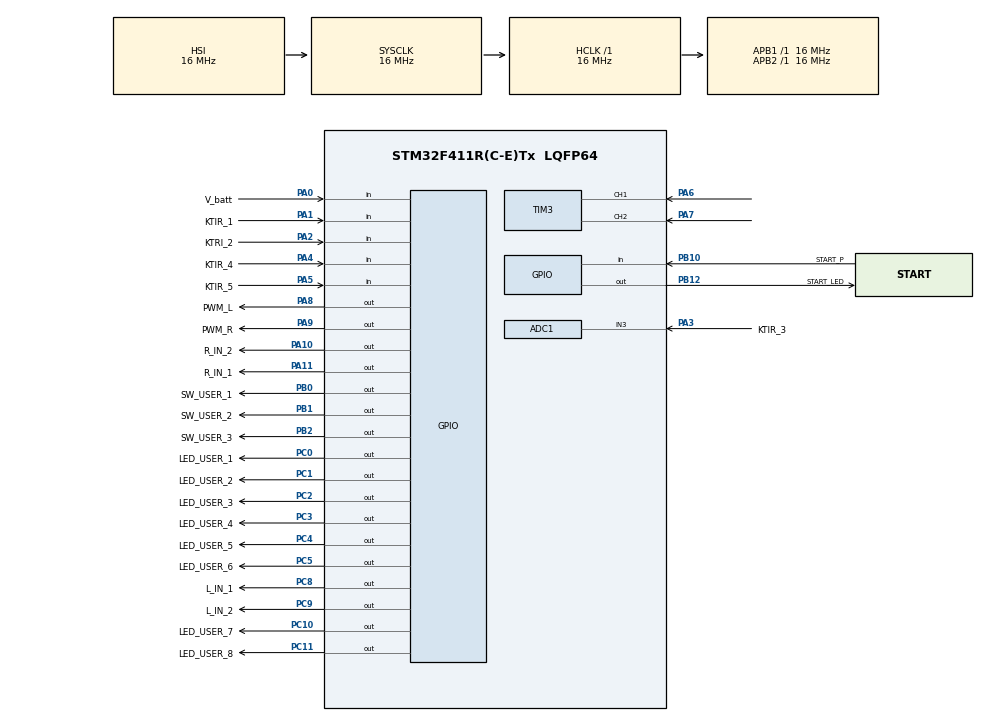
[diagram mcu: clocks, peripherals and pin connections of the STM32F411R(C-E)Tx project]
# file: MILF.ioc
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ADC1.Channel-0\#ChannelRegularConversion=ADC_CHANNEL_3
ADC1.NbrOfConversionFlag=1
ADC1.Rank-0\#ChannelRegularConversion=1
ADC1.SamplingTime-0\#ChannelRegularConversion=ADC_SAMPLETIME_3CYCLES
ADC1.master=1
Mcu.Family=STM32F4
Mcu.Name=STM32F411R(C-E)Tx
Mcu.Package=LQFP64
NVIC.PriorityGroup=NVIC_PRIORITYGROUP_4
PA0-WKUP.GPIO_Label=V_batt
PA0-WKUP.Signal=GPIO_Input
PA1.GPIO_Label=KTIR_1
PA1.Signal=GPIO_Input
PA10.GPIO_Label=R_IN_2
PA10.Signal=GPIO_Output
PA11.GPIO_Label=R_IN_1
PA11.Signal=GPIO_Output
PA13.GPIO_Label=SYS_SWDIO
PA13.Signal=SYS_JTMS-SWDIO
PA14.GPIO_Label=SYS_SWCLK
PA14.Signal=SYS_JTCK-SWCLK
PA2.GPIO_Label=KTRI_2
PA2.Signal=GPIO_Input
PA3.GPIO_Label=KTIR_3
PA3.Signal=ADCx_IN3
PA4.GPIO_Label=KTIR_4
PA4.Signal=GPIO_Input
PA5.GPIO_Label=KTIR_5
PA5.Signal=GPIO_Input
PA6.Signal=S_TIM3_CH1
PA7.Signal=S_TIM3_CH2
PA8.GPIO_Label=PWM_L
PA8.Signal=GPIO_Output
PA9.GPIO_Label=PWM_R
PA9.Signal=GPIO_Output
PB0.GPIO_Label=SW_USER_1
PB0.Signal=GPIO_Output
PB1.GPIO_Label=SW_USER_2
PB1.Signal=GPIO_Output
PB10.GPIO_Label=START_P
PB10.Signal=GPIO_Input
PB12.GPIO_Label=START_LED
PB12.Signal=GPIO_Output
PB2.GPIO_Label=SW_USER_3
PB2.Signal=GPIO_Output
PB6.Signal=USART1_TX
PB7.Signal=USART1_RX
PC0.GPIO_Label=LED_USER_1
PC0.Signal=GPIO_Output
PC1.GPIO_Label=LED_USER_2
PC1.Signal=GPIO_Output
PC10.GPIO_Label=LED_USER_7
PC10.Signal=GPIO_Output
PC11.GPIO_Label=LED_USER_8
PC11.Signal=GPIO_Output
PC2.GPIO_Label=LED_USER_3
PC2.Signal=GPIO_Output
PC3.GPIO_Label=LED_USER_4
PC3.Signal=GPIO_Output
PC4.GPIO_Label=LED_USER_5
PC4.Signal=GPIO_Output
PC5.GPIO_Label=LED_USER_6
PC5.Signal=GPIO_Output
PC6.Signal=USART6_TX
PC7.Signal=USART6_RX
PC8.GPIO_Label=L_IN_1
PC8.Signal=GPIO_Output
PC9.GPIO_Label=L_IN_2
PC9.Signal=GPIO_Output
ProjectManager.HeapSize=0x200
ProjectManager.StackSize=0x400
ProjectManager.TargetToolchain=STM32CubeIDE
RCC.AHBFreq_Value=16000000
RCC.APB1Freq_Value=16000000
RCC.APB2Freq_Value=16000000
RCC.CortexFreq_Value=16000000
RCC.HSE_VALUE=25000000
RCC.HSI_VALUE=16000000
RCC.LSE_VALUE=32768
RCC.SYSCLKFreq_VALUE=16000000
RCC.VCOOutputFreq_Value=192000000
SH.ADCx_IN3.0=ADC1_IN3,IN3
SH.S_TIM3_CH1.0=TIM3_CH1,Encoder_Interface
SH.S_TIM3_CH2.0=TIM3_CH2,Encoder_Interface
board=custom

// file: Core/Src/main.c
/* USER CODE BEGIN Header */
/**
  ******************************************************************************
  * @file           : main.c
  * @brief          : Main program body
  ******************************************************************************
  * @attention
  *
  * <h2><center>&copy; Copyright (c) 2021 STMicroelectronics.
  * All rights reserved.</center></h2>
  *
  * This software component is licensed by ST under BSD 3-Clause license,
  * the "License"; You may not use this file except in compliance with the
  * License. You may obtain a copy of the License at:
  *                        opensource.org/licenses/BSD-3-Clause
  *
  ******************************************************************************
  */
/* USER CODE END Header */
#include "main.h"

ADC_HandleTypeDef hadc1;

TIM_HandleTypeDef htim3;

void SystemClock_Config(void);
static void MX_GPIO_Init(void);
static void MX_ADC1_Init(void);
static void MX_TIM3_Init(void);

int main(void)
{

  /* MCU Configuration--------------------------------------------------------*/

  /* Reset of all peripherals, Initializes the Flash interface and the Systick. */
  HAL_Init();

  /* Configure the system clock */
  SystemClock_Config();

  /* Initialize all configured peripherals */
  MX_GPIO_Init();
  MX_ADC1_Init();
  MX_TIM3_Init();

  /* Infinite loop */
  /* USER CODE BEGIN WHILE */
  while (1)
  {
	  managedir();
    /* USER CODE END WHILE */

  }
}

void SystemClock_Config(void)
{
  RCC_OscInitTypeDef RCC_OscInitStruct = {0};
  RCC_ClkInitTypeDef RCC_ClkInitStruct = {0};

  /** Configure the main internal regulator output voltage
  */
  __HAL_RCC_PWR_CLK_ENABLE();
  __HAL_PWR_VOLTAGESCALING_CONFIG(PWR_REGULATOR_VOLTAGE_SCALE1);
  /** Initializes the RCC Oscillators according to the specified parameters
  * in the RCC_OscInitTypeDef structure.
  */
  RCC_OscInitStruct.OscillatorType = RCC_OSCILLATORTYPE_HSI;
  RCC_OscInitStruct.HSIState = RCC_HSI_ON;
  RCC_OscInitStruct.HSICalibrationValue = RCC_HSICALIBRATION_DEFAULT;
  RCC_OscInitStruct.PLL.PLLState = RCC_PLL_NONE;
  if (HAL_RCC_OscConfig(&RCC_OscInitStruct) != HAL_OK)
  {
    Error_Handler();
  }
  /** Initializes the CPU, AHB and APB buses clocks
  */
  RCC_ClkInitStruct.ClockType = RCC_CLOCKTYPE_HCLK|RCC_CLOCKTYPE_SYSCLK
                              |RCC_CLOCKTYPE_PCLK1|RCC_CLOCKTYPE_PCLK2;
  RCC_ClkInitStruct.SYSCLKSource = RCC_SYSCLKSOURCE_HSI;
  RCC_ClkInitStruct.AHBCLKDivider = RCC_SYSCLK_DIV1;
  RCC_ClkInitStruct.APB1CLKDivider = RCC_HCLK_DIV1;
  RCC_ClkInitStruct.APB2CLKDivider = RCC_HCLK_DIV1;

  if (HAL_RCC_ClockConfig(&RCC_ClkInitStruct, FLASH_LATENCY_0) != HAL_OK)
  {
    Error_Handler();
  }
}

static void MX_ADC1_Init(void)
{

  ADC_ChannelConfTypeDef sConfig = {0};

  /** Configure the global features of the ADC (Clock, Resolution, Data Alignment and number of conversion)
  */
  hadc1.Instance = ADC1;
  hadc1.Init.ClockPrescaler = ADC_CLOCK_SYNC_PCLK_DIV2;
  hadc1.Init.Resolution = ADC_RESOLUTION_12B;
  hadc1.Init.ScanConvMode = DISABLE;
  hadc1.Init.ContinuousConvMode = DISABLE;
  hadc1.Init.DiscontinuousConvMode = DISABLE;
  hadc1.Init.ExternalTrigConvEdge = ADC_EXTERNALTRIGCONVEDGE_NONE;
  hadc1.Init.ExternalTrigConv = ADC_SOFTWARE_START;
  hadc1.Init.DataAlign = ADC_DATAALIGN_RIGHT;
  hadc1.Init.NbrOfConversion = 1;
  hadc1.Init.DMAContinuousRequests = DISABLE;
  hadc1.Init.EOCSelection = ADC_EOC_SINGLE_CONV;
  if (HAL_ADC_Init(&hadc1) != HAL_OK)
  {
    Error_Handler();
  }
  /** Configure for the selected ADC regular channel its corresponding rank in the sequencer and its sample time.
  */
  sConfig.Channel = ADC_CHANNEL_3;
  sConfig.Rank = 1;
  sConfig.SamplingTime = ADC_SAMPLETIME_3CYCLES;
  if (HAL_ADC_ConfigChannel(&hadc1, &sConfig) != HAL_OK)
  {
    Error_Handler();
  }

}

static void MX_TIM3_Init(void)
{

  TIM_Encoder_InitTypeDef sConfig = {0};
  TIM_MasterConfigTypeDef sMasterConfig = {0};

  htim3.Instance = TIM3;
  htim3.Init.Prescaler = 0;
  htim3.Init.CounterMode = TIM_COUNTERMODE_UP;
  htim3.Init.Period = 65535;
  htim3.Init.ClockDivision = TIM_CLOCKDIVISION_DIV1;
  htim3.Init.AutoReloadPreload = TIM_AUTORELOAD_PRELOAD_DISABLE;
  sConfig.EncoderMode = TIM_ENCODERMODE_TI1;
  sConfig.IC1Polarity = TIM_ICPOLARITY_RISING;
  sConfig.IC1Selection = TIM_ICSELECTION_DIRECTTI;
  sConfig.IC1Prescaler = TIM_ICPSC_DIV1;
  sConfig.IC1Filter = 0;
  sConfig.IC2Polarity = TIM_ICPOLARITY_RISING;
  sConfig.IC2Selection = TIM_ICSELECTION_DIRECTTI;
  sConfig.IC2Prescaler = TIM_ICPSC_DIV1;
  sConfig.IC2Filter = 0;
  if (HAL_TIM_Encoder_Init(&htim3, &sConfig) != HAL_OK)
  {
    Error_Handler();
  }
  sMasterConfig.MasterOutputTrigger = TIM_TRGO_RESET;
  sMasterConfig.MasterSlaveMode = TIM_MASTERSLAVEMODE_DISABLE;
  if (HAL_TIMEx_MasterConfigSynchronization(&htim3, &sMasterConfig) != HAL_OK)
  {
    Error_Handler();
  }

}

static void MX_GPIO_Init(void)
{
  GPIO_InitTypeDef GPIO_InitStruct = {0};

  /* GPIO Ports Clock Enable */
  __HAL_RCC_GPIOC_CLK_ENABLE();
  __HAL_RCC_GPIOA_CLK_ENABLE();
  __HAL_RCC_GPIOB_CLK_ENABLE();

  /*Configure GPIO pin Output Level */
  HAL_GPIO_WritePin(GPIOC, LED_USER_1_Pin|LED_USER_2_Pin|LED_USER_3_Pin|LED_USER_4_Pin
                          |LED_USER_5_Pin|LED_USER_6_Pin|L_IN_1_Pin|L_IN_2_Pin
                          |LED_USER_7_Pin|LED_USER_8_Pin, GPIO_PIN_RESET);

  /*Configure GPIO pin Output Level */
  HAL_GPIO_WritePin(GPIOB, SW_USER_1_Pin|SW_USER_2_Pin|SW_USER_3_Pin|START_LED_Pin, GPIO_PIN_RESET);

  /*Configure GPIO pin Output Level */
  HAL_GPIO_WritePin(GPIOA, PWM_L_Pin|PWM_R_Pin|R_IN_2_Pin|R_IN_1_Pin, GPIO_PIN_RESET);

  /*Configure GPIO pins : LED_USER_1_Pin LED_USER_2_Pin LED_USER_3_Pin LED_USER_4_Pin
                           LED_USER_5_Pin LED_USER_6_Pin L_IN_1_Pin L_IN_2_Pin
                           LED_USER_7_Pin LED_USER_8_Pin */
  GPIO_InitStruct.Pin = LED_USER_1_Pin|LED_USER_2_Pin|LED_USER_3_Pin|LED_USER_4_Pin
                          |LED_USER_5_Pin|LED_USER_6_Pin|L_IN_1_Pin|L_IN_2_Pin
                          |LED_USER_7_Pin|LED_USER_8_Pin;
  GPIO_InitStruct.Mode = GPIO_MODE_OUTPUT_PP;
  GPIO_InitStruct.Pull = GPIO_NOPULL;
  GPIO_InitStruct.Speed = GPIO_SPEED_FREQ_LOW;
  HAL_GPIO_Init(GPIOC, &GPIO_InitStruct);

  /*Configure GPIO pins : V_batt_Pin KTIR_1_Pin KTRI_2_Pin KTIR_4_Pin
                           KTIR_5_Pin */
  GPIO_InitStruct.Pin = V_batt_Pin|KTIR_1_Pin|KTRI_2_Pin|KTIR_4_Pin
                          |KTIR_5_Pin;
  GPIO_InitStruct.Mode = GPIO_MODE_INPUT;
  GPIO_InitStruct.Pull = GPIO_NOPULL;
  HAL_GPIO_Init(GPIOA, &GPIO_InitStruct);

  /*Configure GPIO pins : SW_USER_1_Pin SW_USER_2_Pin SW_USER_3_Pin START_LED_Pin */
  GPIO_InitStruct.Pin = SW_USER_1_Pin|SW_USER_2_Pin|SW_USER_3_Pin|START_LED_Pin;
  GPIO_InitStruct.Mode = GPIO_MODE_OUTPUT_PP;
  GPIO_InitStruct.Pull = GPIO_NOPULL;
  GPIO_InitStruct.Speed = GPIO_SPEED_FREQ_LOW;
  HAL_GPIO_Init(GPIOB, &GPIO_InitStruct);

  /*Configure GPIO pin : START_P_Pin */
  GPIO_InitStruct.Pin = START_P_Pin;
  GPIO_InitStruct.Mode = GPIO_MODE_INPUT;
  GPIO_InitStruct.Pull = GPIO_NOPULL;
  HAL_GPIO_Init(START_P_GPIO_Port, &GPIO_InitStruct);

  /*Configure GPIO pins : PC6 PC7 */
  GPIO_InitStruct.Pin = GPIO_PIN_6|GPIO_PIN_7;
  GPIO_InitStruct.Mode = GPIO_MODE_AF_PP;
  GPIO_InitStruct.Pull = GPIO_NOPULL;
  GPIO_InitStruct.Speed = GPIO_SPEED_FREQ_VERY_HIGH;
  GPIO_InitStruct.Alternate = GPIO_AF8_USART6;
  HAL_GPIO_Init(GPIOC, &GPIO_InitStruct);

  /*Configure GPIO pins : PWM_L_Pin PWM_R_Pin R_IN_2_Pin R_IN_1_Pin */
  GPIO_InitStruct.Pin = PWM_L_Pin|PWM_R_Pin|R_IN_2_Pin|R_IN_1_Pin;
  GPIO_InitStruct.Mode = GPIO_MODE_OUTPUT_PP;
  GPIO_InitStruct.Pull = GPIO_NOPULL;
  GPIO_InitStruct.Speed = GPIO_SPEED_FREQ_LOW;
  HAL_GPIO_Init(GPIOA, &GPIO_InitStruct);

  /*Configure GPIO pins : PB6 PB7 */
  GPIO_InitStruct.Pin = GPIO_PIN_6|GPIO_PIN_7;
  GPIO_InitStruct.Mode = GPIO_MODE_AF_PP;
  GPIO_InitStruct.Pull = GPIO_NOPULL;
  GPIO_InitStruct.Speed = GPIO_SPEED_FREQ_VERY_HIGH;
  GPIO_InitStruct.Alternate = GPIO_AF7_USART1;
  HAL_GPIO_Init(GPIOB, &GPIO_InitStruct);

}

void Error_Handler(void)
{
}

/************************ (C) COPYRIGHT STMicroelectronics *****END OF FILE****/
